# PIC32MK1024MCF064 device description
Architecture: MIPS; Family: PIC32MK; Series: PIC32MK
Registers are 32-bit, read-write, no defined reset value unless marked. A register's access mark holds for its fields unless they carry their own. Offsets are from the block's base; [hi:lo] are bit positions; lines under a group give offsets from that group; {n}, {i} and the like mark numbered series; 'fields as' and 'values as' point back to an identical list.

## SB
Instances: SB 0x1f8f0510 in periph_ssx
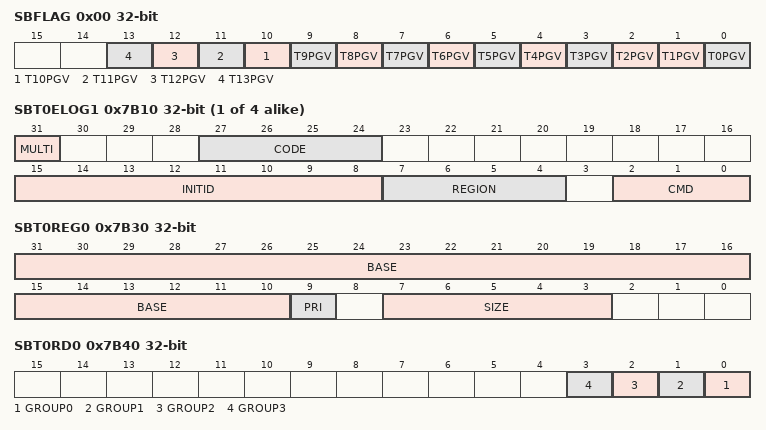
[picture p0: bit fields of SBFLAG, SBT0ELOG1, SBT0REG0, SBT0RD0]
0x00 SBFLAG ro — System Bus Status Flag Register
  [all] fields
    1=Target is reporting a Permission Group (PG) violation; 0=Target is not reporting a PG violation
  [n] T{n}PGV (n=2..13) — Target {n} Permission Group Violation Status bits
  [1] T1PGV — Target 1Permission Group Violation Status bits
  [0] T0PGV — Target 0 Permission Group Violation Status bits
{0x7B10+0x400*i} SBT{i}ELOG1 ro (i=0..3) — System Bus Target 'x' Error Log Register 1
  [31] MULTI — Multiple Permission Violations Status bit
    1=Multiple errors have been detected; 0=No multiple errors have been detected
  [27:24] CODE — Error Code bits
    3=Permission violation; 0=No error
  [15:8] INITID — Initiator ID of Requester bits
    14=Crypto Engine; 13=Flash Controller; 12=SQI1; 11=CAN2; 10=CAN1; 9=Ethernet Write; 8=Ethernet Read; 7=USB; 6=DMA Write (DMAPRI (CFGCON) = 1); 5=DMA Write (DMAPRI (CFGCON) = 0); 4=DMA Read (DMAPRI (CFGCON) = 1); 3=DMA Read (DMAPRI (CFGCON) = 0); 2=CPU (CPUPRI (CFGCON) = 1); 1=CPU (CPUPRI (CFGCON) = 0)
  [7:4] REGION — Requested Region Number bits
    1111 - 0000=Targets region that reported a permission group violation
  [2:0] CMD — Transaction Command of the Requester bits
    5=Write (a non-posted write); 3=Read (a locked read caused by a Read-Modify-Write transaction); 2=Read; 1=Write; 0=Idle
{0x7B14+0x400*i} SBT{i}ELOG2 ro (i=0..3) — System Bus Target 'x' Error Log Register 2
  [1:0] GROUP — Requested Permissions Group bits
    {v}=Group {v} (v=0..3)
{0x7B18+0x400*i} SBT{i}ECON (i=0..3) — System Bus Target 'x' Error Control Register
  [24] ERRP — Error Control bit
    1=Report protection group violation errors; 0=Do not report protection group violation errors
{0x7B20+0x400*i} SBT{i}ECLRS ro (i=0..3) — System Bus Target 'x' Single Error Clear Register
  [0] CLEAR
{0x7B28+0x400*i} SBT{i}ECLRM ro (i=0..3) — System Bus Target 'x' Multiple Error Clear Register
  [0] CLEAR
0x7B30 SBT0REG0
  [31:10] BASE
  [9] PRI — Region Priority Level bit
    1=Level 2; 0=Level 1
  [7:3] SIZE — Region Size bits
    0=Region is not present; 1=Region is 1024 bytes; 2=Region is 2048 bytes; 3=Region is 4096 bytes
0x7B40 SBT0RD0
  [n] GROUP{n} (n=0..3) — Group{n} Read Permissions bits
    1=Privilege Group {n} has read permission; 0=Privilege Group {n} does not have read permission
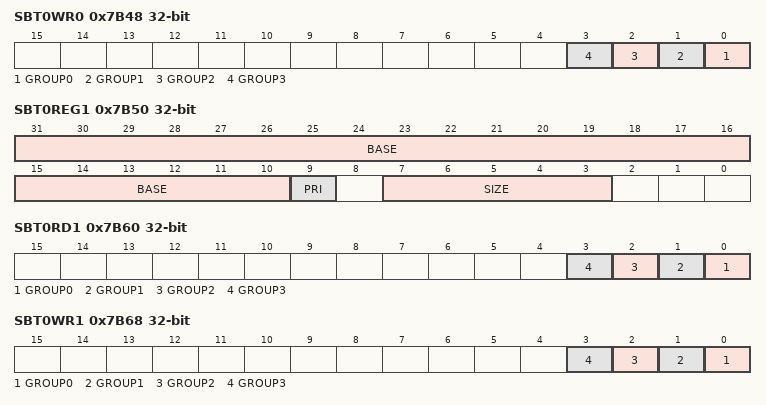
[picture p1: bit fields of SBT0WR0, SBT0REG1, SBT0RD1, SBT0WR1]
0x7B48 SBT0WR0
  [n] GROUP{n} (n=0..3) — Group {n} Write Permissions bits
    1=Privilege Group {n} has write permission; 0=Privilege Group {n} does not have write permission
0x7B50 SBT0REG1
  fields as SBT0REG0
0x7B60 SBT0RD1
  fields as SBT0RD0
0x7B68 SBT0WR1
  fields as SBT0WR0
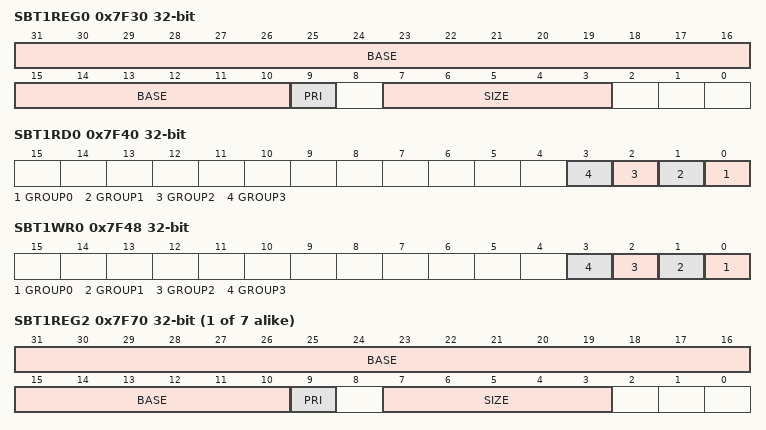
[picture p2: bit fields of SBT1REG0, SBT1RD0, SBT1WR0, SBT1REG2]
0x7F30 SBT1REG0
  fields as SBT0REG0
0x7F40 SBT1RD0
  fields as SBT0RD0
0x7F48 SBT1WR0
  fields as SBT0WR0
{0x7F30+0x20*i} SBT1REG{i} (i=2..8)
  fields as SBT0REG0
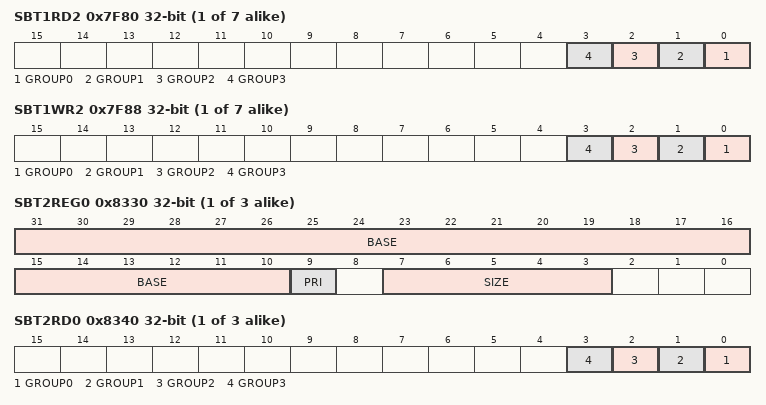
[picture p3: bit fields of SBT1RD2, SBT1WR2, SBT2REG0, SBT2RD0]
{0x7F40+0x20*i} SBT1RD{i} (i=2..8)
  fields as SBT0RD0
{0x7F48+0x20*i} SBT1WR{i} (i=2..8)
  fields as SBT0WR0
{0x8330+0x20*i} SBT2REG{i} (i=0..2)
  fields as SBT0REG0
{0x8340+0x20*i} SBT2RD{i} (i=0..2)
  fields as SBT0RD0
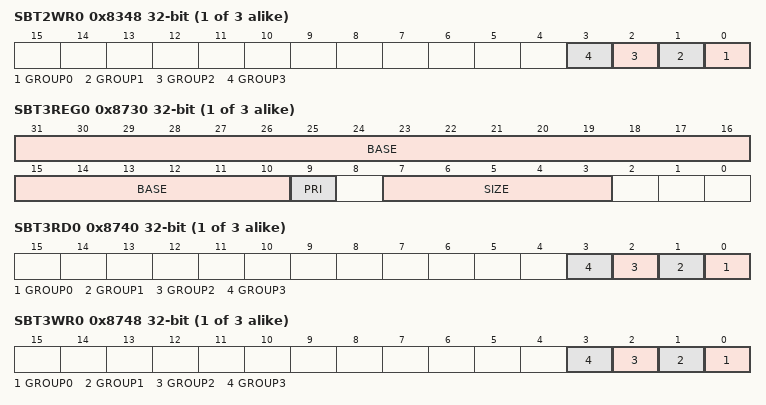
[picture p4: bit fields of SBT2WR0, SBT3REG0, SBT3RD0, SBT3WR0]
{0x8348+0x20*i} SBT2WR{i} (i=0..2)
  fields as SBT0WR0
{0x8730+0x20*i} SBT3REG{i} (i=0..2)
  fields as SBT0REG0
{0x8740+0x20*i} SBT3RD{i} (i=0..2)
  fields as SBT0RD0
{0x8748+0x20*i} SBT3WR{i} (i=0..2)
  fields as SBT0WR0

## TMR1
Instances: TMR1 0x1f820000 in periph_pb2_std
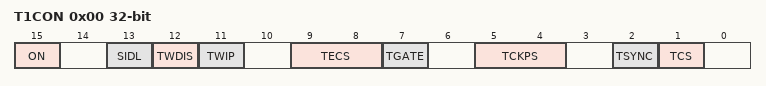
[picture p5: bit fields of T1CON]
0x00 T1CON — TYPE A TIMER CONTROL REGISTER
  [15] ON — Timer On bit
    1=Timer is enabled; 0=Timer is disabled
  [13] SIDL — Stop in Idle Mode bit
    1=Discontinue operation when device enters Idle mode; 0=CONTINUE (Continue operation even in Idle mode)
  [12] TWDIS — Asynchronous Timer Write Disable bit
    1=Writes to TMR1 are ignored until pending write operation completes; 0=Back-to-back writes are enabled (Legacy Asynchronous Timer functionality)
  [11] TWIP — Asynchronous Timer Write in Progress bit
    1=(In Asynchronous Timer mode) Asynchronous write to TMR1 register in progress / (In Synchronous Timer mode)bit is read as 0; 0=In Asynchronous Timer mode Asynchronous write to TMR1 register complete / (In Synchronous Timer mode)bit is read as 0
  [9:8] TECS — Timer1 External Clock Selection bits
    2=External clock comes from the LPRC; 1=External clock comes from the T1CK pin; 0=External clock comes from the SOSC
  [7] TGATE — Timer Gated Time Accumulation Enable bit
    1=(When TCS is 0) Gated time accumulation is enabled / (When TCS is 1) bit is ignored; 0=(When TCS is 0) Gated time accumulation is disabled / (When TCS is 1) bit is ignored
  [5:4] TCKPS — Timer Input Clock Prescale Select bits
    3=1:256 prescale value; 2=1:64 prescale value; 1=1:8 prescale value; 0=1:1 prescale value
  [2] TSYNC — Timer External Clock Input Synchronization Selection bit
    1=(When TCS is 1) External clock input is synchronized / (When TCS is 0) This bit is ignored; 0=(When TCS is 1) External clock input is not synchronized / (When TCS is 0) This bit is ignored
  [1] TCS — Timer Clock Source Select bit
    1=External clock is defined by the TECS bits; 0=INT_CLK (Internal peripheral clock)
0x10 TMR1
0x20 PR1

## TMR
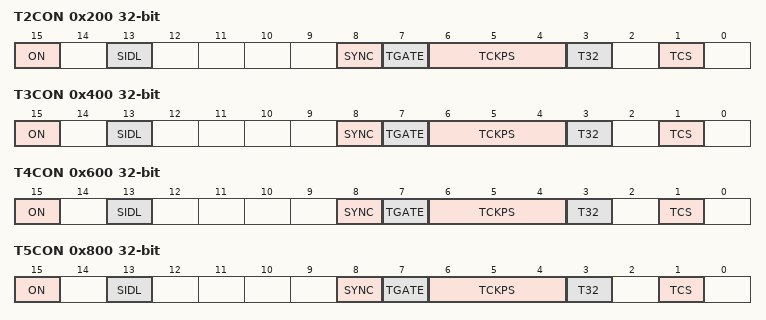
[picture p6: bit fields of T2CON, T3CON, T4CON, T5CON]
0x200 T2CON — Timer Configuration
  [15] ON — Timer On bit
    1=ON (Module is enabled); 0=OFF (Module is disabled)
  [13] SIDL — Stop in Idle Mode bit
    1=STOP (Discontinue operation when device enters Idle mode); 0=CONTINUE (Continue operation even in Idle mode)
  [8] SYNC — Synchronized Timer Start/Stop Enable bit
    1=ENABLED (Synchronized timer Start/Stop is enabled); 0=DISABLED (Synchronized timer Start/Stop is disabled)
  [7] TGATE — Timer Gated Time Accumulation Enable bit
    1=ENABLED (Gated time accumulation is enabled); 0=DISABLED (Gated time accumulation is disabled)
  [6:4] TCKPS — Timer Input Clock Prescale Select bits
    7=DIV_256 (1:256 prescale value); 6=DIV_64 (1:64 prescale value); 5=DIV_32 (1:32 prescale value); 4=DIV_16 (1:16 prescale value); 3=DIV_8 (1:8 prescale value); 2=DIV_4 (1:4 prescale value); 1=DIV_2 (1:2 prescale value); 0=DIV_1 (1:1 prescale value)
  [3] T32 — 32-Bit Timer Mode Select bit
    1=32_BIT (32-bit Timer mode); 0=16_BIT (16-bit Timer mode)
  [1] TCS — Timer Clock Source Select bit
    1=EXT_CLK (External clock from TxCK pin); 0=INT_CLK (Internal peripheral clock)
0x210 TMR2 — Timer
0x220 PR2 — Timer Period
0x400 T3CON — Timer Configuration
  fields as T2CON
0x410 TMR3 — Timer
0x420 PR3 — Timer Period
0x600 T4CON — Timer Configuration
  fields as T2CON
0x610 TMR4 — Timer
0x620 PR4 — Timer Period
0x800 T5CON — Timer Configuration
  fields as T2CON
0x810 TMR5 — Timer
0x820 PR5 — Timer Period
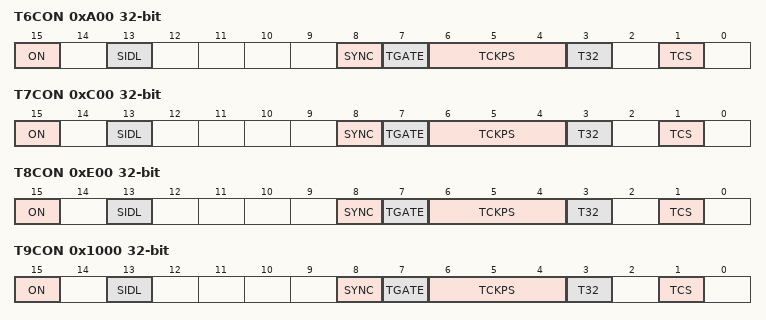
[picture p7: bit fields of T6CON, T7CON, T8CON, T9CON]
0xA00 T6CON — Timer Configuration
  fields as T2CON
0xA10 TMR6 — Timer
0xA20 PR6 — Timer Period
0xC00 T7CON — Timer Configuration
  fields as T2CON
0xC10 TMR7 — Timer
0xC20 PR7 — Timer Period
0xE00 T8CON — Timer Configuration
  fields as T2CON
0xE10 TMR8 — Timer
0xE20 PR8 — Timer Period
0x1000 T9CON — Timer Configuration
  fields as T2CON
0x1010 TMR9 — Timer
0x1020 PR9 — Timer Period

## WDT
Instances: WDT 0x1f800c00 in periph_pb1_std
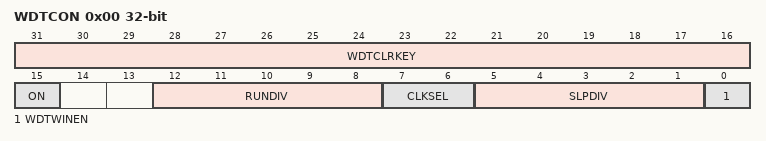
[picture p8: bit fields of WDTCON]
0x00 WDTCON — Watchdog Timer Control Register
  [31:16] WDTCLRKEY
  [15] ON — Watchdog Timer Enable bit
    1=The WDT is enabled; 0=The WDT is disabled
  [12:8] RUNDIV
  [7:6] CLKSEL
  [5:1] SLPDIV
  [0] WDTWINEN — Watchdog Timer Window Enable bit
    1=Enable windowed Watchdog Timer; 0=Disable windowed Watchdog Timer
